# f29h85x_sent_cfg_regs register map
Vendor: Texas Instruments
Peripheral module from a debugger description file (folder C29).
Registers are 32-bit, read-only, no defined reset value unless marked. A register's access mark holds for its fields unless they carry their own. Offsets are as the file gives them; lines under a group give offsets from that group; [hi:lo] are bit positions; {n}, {i} and the like mark numbered series; 'fields as' and 'values as' point back to an identical list; <NAME> marks a mode.

## SENT_CFG — SENT CFG Registers
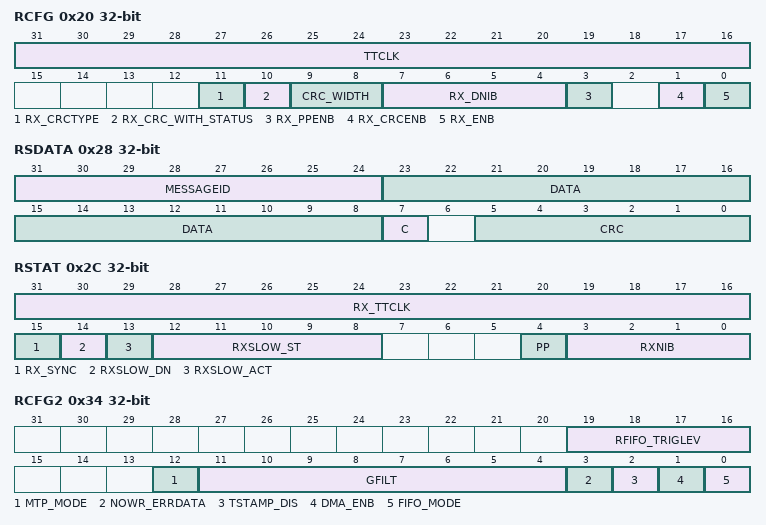
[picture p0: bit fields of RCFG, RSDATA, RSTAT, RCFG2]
0x20 RCFG access per field
  [31:16] TTCLK rw, [11] RX_CRCTYPE rw, [10] RX_CRC_WITH_STATUS rw, [9:8] CRC_WIDTH rw, [7:4] RX_DNIB rw, [3] RX_PPENB rw, [1] RX_CRCENB rw, [0] RX_ENB rw
0x24 RFDATA
  [31:0] FIFO_RDATA
0x28 RSDATA
  [31:24] MESSAGEID, [23:8] DATA, [7] C, [5:0] CRC
0x2C RSTAT
  [31:16] RX_TTCLK, [15] RX_SYNC, [14] RXSLOW_DN, [13] RXSLOW_ACT, [12:8] RXSLOW_ST, [4] PP, [3:0] RXNIB
0x34 RCFG2 access per field
  [19:16] RFIFO_TRIGLEV rw, [12] MTP_MODE rw, [11:4] GFILT rw, [3] NOWR_ERRDATA rw, [2] TSTAMP_DIS rw, [1] DMA_ENB rw, [0] FIFO_MODE rw
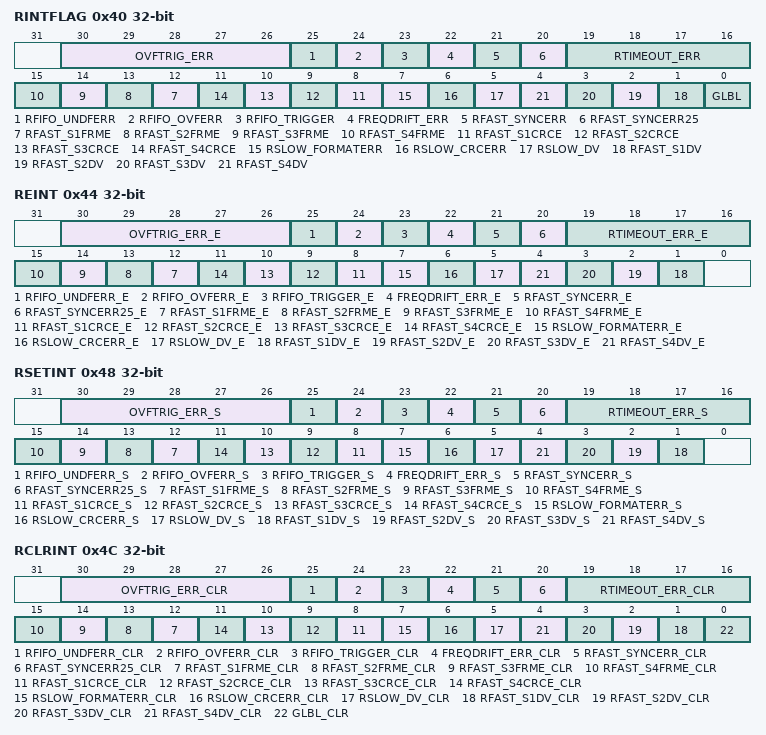
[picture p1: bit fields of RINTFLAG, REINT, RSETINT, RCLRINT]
0x40 RINTFLAG
  [30:26] OVFTRIG_ERR, [25] RFIFO_UNDFERR, [24] RFIFO_OVFERR, [23] RFIFO_TRIGGER, [22] FREQDRIFT_ERR, [21] RFAST_SYNCERR, [20] RFAST_SYNCERR25, [19:16] RTIMEOUT_ERR, [n+11] RFAST_S{n}FRME (n=1..4), [n+7] RFAST_S{n}CRCE (n=1..4), [7] RSLOW_FORMATERR, [6] RSLOW_CRCERR, [5] RSLOW_DV, [n] RFAST_S{n}DV (n=1..4), [0] GLBL
0x44 REINT access per field
  [30:26] OVFTRIG_ERR_E rw, [25] RFIFO_UNDFERR_E rw, [24] RFIFO_OVFERR_E rw, [23] RFIFO_TRIGGER_E rw, [22] FREQDRIFT_ERR_E rw, [21] RFAST_SYNCERR_E rw, [20] RFAST_SYNCERR25_E rw, [19:16] RTIMEOUT_ERR_E rw, [n+11] RFAST_S{n}FRME_E rw (n=1..4), [n+7] RFAST_S{n}CRCE_E rw (n=1..4), [7] RSLOW_FORMATERR_E rw, [6] RSLOW_CRCERR_E rw, [5] RSLOW_DV_E rw, [n] RFAST_S{n}DV_E rw (n=1..4)
0x48 RSETINT rw
  [30:26] OVFTRIG_ERR_S, [25] RFIFO_UNDFERR_S, [24] RFIFO_OVFERR_S, [23] RFIFO_TRIGGER_S, [22] FREQDRIFT_ERR_S, [21] RFAST_SYNCERR_S, [20] RFAST_SYNCERR25_S, [19:16] RTIMEOUT_ERR_S, [n+11] RFAST_S{n}FRME_S (n=1..4), [n+7] RFAST_S{n}CRCE_S (n=1..4), [7] RSLOW_FORMATERR_S, [6] RSLOW_CRCERR_S, [5] RSLOW_DV_S, [n] RFAST_S{n}DV_S (n=1..4)
0x4C RCLRINT rw
  [30:26] OVFTRIG_ERR_CLR, [25] RFIFO_UNDFERR_CLR, [24] RFIFO_OVFERR_CLR, [23] RFIFO_TRIGGER_CLR, [22] FREQDRIFT_ERR_CLR, [21] RFAST_SYNCERR_CLR, [20] RFAST_SYNCERR25_CLR, [19:16] RTIMEOUT_ERR_CLR, [n+11] RFAST_S{n}FRME_CLR (n=1..4), [n+7] RFAST_S{n}CRCE_CLR (n=1..4), [7] RSLOW_FORMATERR_CLR, [6] RSLOW_CRCERR_CLR, [5] RSLOW_DV_CLR, [n] RFAST_S{n}DV_CLR (n=1..4), [0] GLBL_CLR
0x50 CSENT_SWR rw
  [0] SWR
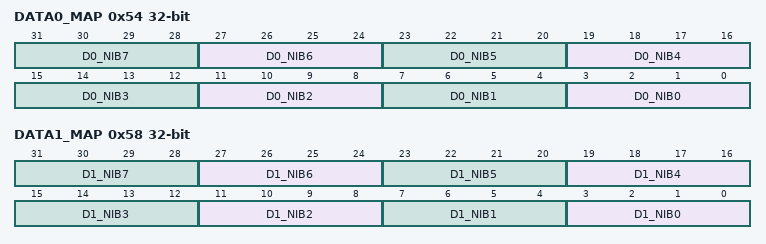
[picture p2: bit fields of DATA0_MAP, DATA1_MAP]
0x54 DATA0_MAP rw
  [4n+3:4n] D0_NIB{n} (n=0..7)
0x58 DATA1_MAP rw
  [4n+3:4n] D1_NIB{n} (n=0..7)
0x5C CSENT_TO rw
  [31:0] TO_VAL
0x60 CSENT_RXD
  [0] RXD_I_R
0x64 RXVAL_CNT
  [7:0] RXVALID_CNT_R
0x68 RXDEDGE_CNT
  [7:0] RXDEDGE_CNT_R
0x6C SWR_RXVAL_CNT rw
  [0] SWR_RXVAL_CNT
0x70 SWR_RXDEDGE_CNT rw
  [0] SWR_RXDEDGE_CNT
0x7C CSENT_VERSION
